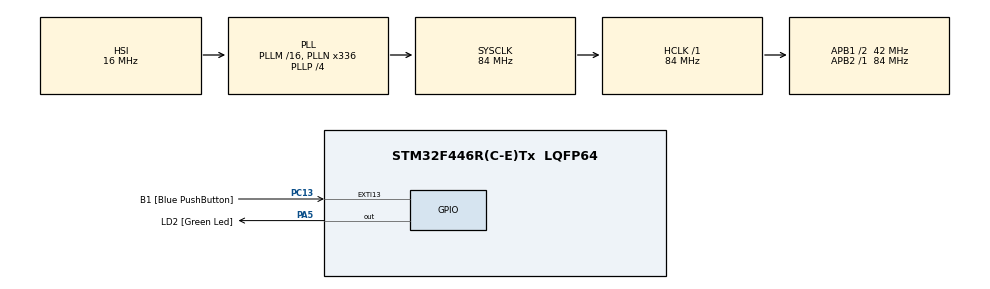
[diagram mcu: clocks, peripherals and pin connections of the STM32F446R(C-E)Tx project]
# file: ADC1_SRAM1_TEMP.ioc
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ADC1.Channel-0\#ChannelRegularConversion=ADC_CHANNEL_TEMPSENSOR
ADC1.Channel-1\#ChannelRegularConversion=ADC_CHANNEL_TEMPSENSOR
ADC1.Channel-10\#ChannelRegularConversion=ADC_CHANNEL_TEMPSENSOR
ADC1.Channel-11\#ChannelRegularConversion=ADC_CHANNEL_TEMPSENSOR
ADC1.Channel-12\#ChannelRegularConversion=ADC_CHANNEL_TEMPSENSOR
ADC1.Channel-13\#ChannelRegularConversion=ADC_CHANNEL_TEMPSENSOR
ADC1.Channel-14\#ChannelRegularConversion=ADC_CHANNEL_TEMPSENSOR
ADC1.Channel-15\#ChannelRegularConversion=ADC_CHANNEL_TEMPSENSOR
ADC1.Channel-2\#ChannelRegularConversion=ADC_CHANNEL_TEMPSENSOR
ADC1.Channel-3\#ChannelRegularConversion=ADC_CHANNEL_TEMPSENSOR
ADC1.Channel-4\#ChannelRegularConversion=ADC_CHANNEL_TEMPSENSOR
ADC1.Channel-5\#ChannelRegularConversion=ADC_CHANNEL_TEMPSENSOR
ADC1.Channel-6\#ChannelRegularConversion=ADC_CHANNEL_TEMPSENSOR
ADC1.Channel-7\#ChannelRegularConversion=ADC_CHANNEL_TEMPSENSOR
ADC1.Channel-8\#ChannelRegularConversion=ADC_CHANNEL_TEMPSENSOR
ADC1.Channel-9\#ChannelRegularConversion=ADC_CHANNEL_TEMPSENSOR
ADC1.ClockPrescaler=ADC_CLOCK_SYNC_PCLK_DIV4
ADC1.ContinuousConvMode=ENABLE
ADC1.DMAContinuousRequests=ENABLE
ADC1.DataAlign=ADC_DATAALIGN_RIGHT
ADC1.DiscontinuousConvMode=DISABLE
ADC1.EOCSelection=ADC_EOC_SINGLE_CONV
ADC1.EnableAnalogWatchDog=false
ADC1.ExternalTrigConv=ADC_SOFTWARE_START
ADC1.ExternalTrigConvEdge=ADC_EXTERNALTRIGCONVEDGE_NONE
ADC1.InjNumberOfConversion=0
ADC1.NbrOfConversion=16
ADC1.NbrOfConversionFlag=1
ADC1.Rank-0\#ChannelRegularConversion=1
ADC1.Rank-1\#ChannelRegularConversion=2
ADC1.Rank-10\#ChannelRegularConversion=11
ADC1.Rank-11\#ChannelRegularConversion=12
ADC1.Rank-12\#ChannelRegularConversion=13
ADC1.Rank-13\#ChannelRegularConversion=14
ADC1.Rank-14\#ChannelRegularConversion=15
ADC1.Rank-15\#ChannelRegularConversion=16
ADC1.Rank-2\#ChannelRegularConversion=3
ADC1.Rank-3\#ChannelRegularConversion=4
ADC1.Rank-4\#ChannelRegularConversion=5
ADC1.Rank-5\#ChannelRegularConversion=6
ADC1.Rank-6\#ChannelRegularConversion=7
ADC1.Rank-7\#ChannelRegularConversion=8
ADC1.Rank-8\#ChannelRegularConversion=9
ADC1.Rank-9\#ChannelRegularConversion=10
ADC1.Resolution=ADC_RESOLUTION_12B
ADC1.SamplingTime-0\#ChannelRegularConversion=ADC_SAMPLETIME_3CYCLES
ADC1.SamplingTime-1\#ChannelRegularConversion=ADC_SAMPLETIME_3CYCLES
ADC1.SamplingTime-10\#ChannelRegularConversion=ADC_SAMPLETIME_3CYCLES
ADC1.SamplingTime-11\#ChannelRegularConversion=ADC_SAMPLETIME_3CYCLES
ADC1.SamplingTime-12\#ChannelRegularConversion=ADC_SAMPLETIME_3CYCLES
ADC1.SamplingTime-13\#ChannelRegularConversion=ADC_SAMPLETIME_3CYCLES
ADC1.SamplingTime-14\#ChannelRegularConversion=ADC_SAMPLETIME_3CYCLES
ADC1.SamplingTime-15\#ChannelRegularConversion=ADC_SAMPLETIME_3CYCLES
ADC1.SamplingTime-2\#ChannelRegularConversion=ADC_SAMPLETIME_3CYCLES
ADC1.SamplingTime-3\#ChannelRegularConversion=ADC_SAMPLETIME_3CYCLES
ADC1.SamplingTime-4\#ChannelRegularConversion=ADC_SAMPLETIME_3CYCLES
ADC1.SamplingTime-5\#ChannelRegularConversion=ADC_SAMPLETIME_3CYCLES
ADC1.SamplingTime-6\#ChannelRegularConversion=ADC_SAMPLETIME_3CYCLES
ADC1.SamplingTime-7\#ChannelRegularConversion=ADC_SAMPLETIME_3CYCLES
ADC1.SamplingTime-8\#ChannelRegularConversion=ADC_SAMPLETIME_3CYCLES
ADC1.SamplingTime-9\#ChannelRegularConversion=ADC_SAMPLETIME_3CYCLES
ADC1.ScanConvMode=DISABLE
ADC1.master=1
Dma.ADC1.0.Direction=DMA_PERIPH_TO_MEMORY
Dma.ADC1.0.FIFOMode=DMA_FIFOMODE_ENABLE
Dma.ADC1.0.FIFOThreshold=DMA_FIFO_THRESHOLD_FULL
Dma.ADC1.0.Instance=DMA2_Stream4
Dma.ADC1.0.MemBurst=DMA_MBURST_SINGLE
Dma.ADC1.0.MemDataAlignment=DMA_MDATAALIGN_HALFWORD
Dma.ADC1.0.MemInc=DMA_MINC_ENABLE
Dma.ADC1.0.Mode=DMA_NORMAL
Dma.ADC1.0.PeriphBurst=DMA_PBURST_SINGLE
Dma.ADC1.0.PeriphDataAlignment=DMA_PDATAALIGN_HALFWORD
Dma.ADC1.0.PeriphInc=DMA_PINC_DISABLE
Dma.ADC1.0.Priority=DMA_PRIORITY_LOW
Dma.Request0=ADC1
Mcu.Family=STM32F4
Mcu.Name=STM32F446R(C-E)Tx
Mcu.Package=LQFP64
NVIC.DMA2_Stream4_IRQn=true\:0\:0\:false\:false\:true\:false
NVIC.EXTI15_10_IRQn=true\:0\:0\:false\:false\:true\:true
NVIC.PriorityGroup=NVIC_PRIORITYGROUP_0
PA13.GPIO_Label=TMS
PA13.Signal=SYS_JTMS-SWDIO
PA14.GPIO_Label=TCK
PA14.Signal=SYS_JTCK-SWCLK
PA2.GPIO_Label=USART_TX
PA2.Signal=USART2_TX
PA3.GPIO_Label=USART_RX
PA3.Signal=USART2_RX
PA5.GPIO_Label=LD2 [Green Led]
PA5.Signal=GPIO_Output
PB3.GPIO_Label=SWO
PB3.Signal=SYS_JTDO-SWO
PC13.GPIO_Label=B1 [Blue PushButton]
PC13.GPIO_ModeDefaultEXTI=GPIO_MODE_IT_FALLING
PC13.Signal=GPXTI13
PC14-OSC32_IN.Signal=RCC_OSC32_IN
PC15-OSC32_OUT.Signal=RCC_OSC32_OUT
PH0-OSC_IN.Signal=RCC_OSC_IN
PH1-OSC_OUT.Signal=RCC_OSC_OUT
ProjectManager.HeapSize=0x200
ProjectManager.StackSize=0x400
ProjectManager.TargetToolchain=MDK-ARM V5
RCC.AHBFreq_Value=84000000
RCC.APB1CLKDivider=RCC_HCLK_DIV2
RCC.APB1Freq_Value=42000000
RCC.APB1TimFreq_Value=84000000
RCC.APB2Freq_Value=84000000
RCC.APB2TimFreq_Value=84000000
RCC.CortexFreq_Value=84000000
RCC.FLatency-AdvancedSettings=FLASH_LATENCY_2
RCC.HCLKFreq_Value=84000000
RCC.HSE_VALUE=8000000
RCC.HSI_VALUE=16000000
RCC.LSE_VALUE=32768
RCC.PLLN=336
RCC.PLLP=RCC_PLLP_DIV4
RCC.SYSCLKFreq_VALUE=84000000
RCC.SYSCLKSource=RCC_SYSCLKSOURCE_PLLCLK
RCC.USBFreq_Value=168000000
RCC.VCOOutputFreq_Value=336000000
VP_ADC1_TempSens_Input.Mode=IN-TempSens
board=NUCLEO-F446RE

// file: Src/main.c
/**
  ******************************************************************************
  * File Name          : main.c
  * Description        : Main program body
  ******************************************************************************
  ** This notice applies to any and all portions of this file
  * that are not between comment pairs USER CODE BEGIN and
  * USER CODE END. Other portions of this file, whether
  * inserted by the user or by software development tools
  * are owned by their respective copyright owners.
  *
  * COPYRIGHT(c) 2018 STMicroelectronics
  *
  * Redistribution and use in source and binary forms, with or without modification,
  * are permitted provided that the following conditions are met:
  *   1. Redistributions of source code must retain the above copyright notice,
  *      this list of conditions and the following disclaimer.
  *   2. Redistributions in binary form must reproduce the above copyright notice,
  *      this list of conditions and the following disclaimer in the documentation
  *      and/or other materials provided with the distribution.
  *   3. Neither the name of STMicroelectronics nor the names of its contributors
  *      may be used to endorse or promote products derived from this software
  *      without specific prior written permission.
  *
  * THIS SOFTWARE IS PROVIDED BY THE COPYRIGHT HOLDERS AND CONTRIBUTORS "AS IS"
  * AND ANY EXPRESS OR IMPLIED WARRANTIES, INCLUDING, BUT NOT LIMITED TO, THE
  * IMPLIED WARRANTIES OF MERCHANTABILITY AND FITNESS FOR A PARTICULAR PURPOSE ARE
  * DISCLAIMED. IN NO EVENT SHALL THE COPYRIGHT HOLDER OR CONTRIBUTORS BE LIABLE
  * FOR ANY DIRECT, INDIRECT, INCIDENTAL, SPECIAL, EXEMPLARY, OR CONSEQUENTIAL
  * DAMAGES (INCLUDING, BUT NOT LIMITED TO, PROCUREMENT OF SUBSTITUTE GOODS OR
  * SERVICES; LOSS OF USE, DATA, OR PROFITS; OR BUSINESS INTERRUPTION) HOWEVER
  * CAUSED AND ON ANY THEORY OF LIABILITY, WHETHER IN CONTRACT, STRICT LIABILITY,
  * OR TORT (INCLUDING NEGLIGENCE OR OTHERWISE) ARISING IN ANY WAY OUT OF THE USE
  * OF THIS SOFTWARE, EVEN IF ADVISED OF THE POSSIBILITY OF SUCH DAMAGE.
  *
  ******************************************************************************
  */

#include "main.h"
#include "stm32f4xx_hal.h"

ADC_HandleTypeDef hadc1;
DMA_HandleTypeDef hdma_adc1;

/* USER CODE BEGIN PV */
/* Private variables ---------------------------------------------------------*/

/* USER CODE END PV */

void SystemClock_Config(void);
static void MX_GPIO_Init(void);
static void MX_DMA_Init(void);
static void MX_ADC1_Init(void);

/* USER CODE BEGIN PFP */
/* Private function prototypes -----------------------------------------------*/

/* USER CODE END PFP */

int main(void)
{

  /* MCU Configuration----------------------------------------------------------*/

  /* Reset of all peripherals, Initializes the Flash interface and the Systick. */
  HAL_Init();

  /* Configure the system clock */
  SystemClock_Config();

  /* Initialize all configured peripherals */
  MX_GPIO_Init();
  MX_DMA_Init();
  MX_ADC1_Init();

  /* Infinite loop */
  while (1)
  {

  }

}

/** System Clock Configuration
*/
void SystemClock_Config(void)
{

  RCC_OscInitTypeDef RCC_OscInitStruct;
  RCC_ClkInitTypeDef RCC_ClkInitStruct;

    /**Configure the main internal regulator output voltage
    */
  __HAL_RCC_PWR_CLK_ENABLE();

  __HAL_PWR_VOLTAGESCALING_CONFIG(PWR_REGULATOR_VOLTAGE_SCALE3);

    /**Initializes the CPU, AHB and APB busses clocks
    */
  RCC_OscInitStruct.OscillatorType = RCC_OSCILLATORTYPE_HSI;
  RCC_OscInitStruct.HSIState = RCC_HSI_ON;
  RCC_OscInitStruct.HSICalibrationValue = 16;
  RCC_OscInitStruct.PLL.PLLState = RCC_PLL_ON;
  RCC_OscInitStruct.PLL.PLLSource = RCC_PLLSOURCE_HSI;
  RCC_OscInitStruct.PLL.PLLM = 16;
  RCC_OscInitStruct.PLL.PLLN = 336;
  RCC_OscInitStruct.PLL.PLLP = RCC_PLLP_DIV4;
  RCC_OscInitStruct.PLL.PLLQ = 2;
  RCC_OscInitStruct.PLL.PLLR = 2;
  if (HAL_RCC_OscConfig(&RCC_OscInitStruct) != HAL_OK)
  {
    _Error_Handler(__FILE__, __LINE__);
  }

    /**Initializes the CPU, AHB and APB busses clocks
    */
  RCC_ClkInitStruct.ClockType = RCC_CLOCKTYPE_HCLK|RCC_CLOCKTYPE_SYSCLK
                              |RCC_CLOCKTYPE_PCLK1|RCC_CLOCKTYPE_PCLK2;
  RCC_ClkInitStruct.SYSCLKSource = RCC_SYSCLKSOURCE_PLLCLK;
  RCC_ClkInitStruct.AHBCLKDivider = RCC_SYSCLK_DIV1;
  RCC_ClkInitStruct.APB1CLKDivider = RCC_HCLK_DIV2;
  RCC_ClkInitStruct.APB2CLKDivider = RCC_HCLK_DIV1;

  if (HAL_RCC_ClockConfig(&RCC_ClkInitStruct, FLASH_LATENCY_2) != HAL_OK)
  {
    _Error_Handler(__FILE__, __LINE__);
  }

    /**Configure the Systick interrupt time
    */
  HAL_SYSTICK_Config(HAL_RCC_GetHCLKFreq()/1000);

    /**Configure the Systick
    */
  HAL_SYSTICK_CLKSourceConfig(SYSTICK_CLKSOURCE_HCLK);

  /* SysTick_IRQn interrupt configuration */
  HAL_NVIC_SetPriority(SysTick_IRQn, 0, 0);
}

/* ADC1 init function */
static void MX_ADC1_Init(void)
{

  ADC_ChannelConfTypeDef sConfig;

    /**Configure the global features of the ADC (Clock, Resolution, Data Alignment and number of conversion)
    */
  hadc1.Instance = ADC1;
  hadc1.Init.ClockPrescaler = ADC_CLOCK_SYNC_PCLK_DIV4;
  hadc1.Init.Resolution = ADC_RESOLUTION_12B;
  hadc1.Init.ScanConvMode = DISABLE;
  hadc1.Init.ContinuousConvMode = ENABLE;
  hadc1.Init.DiscontinuousConvMode = DISABLE;
  hadc1.Init.ExternalTrigConvEdge = ADC_EXTERNALTRIGCONVEDGE_NONE;
  hadc1.Init.ExternalTrigConv = ADC_SOFTWARE_START;
  hadc1.Init.DataAlign = ADC_DATAALIGN_RIGHT;
  hadc1.Init.NbrOfConversion = 16;
  hadc1.Init.DMAContinuousRequests = ENABLE;
  hadc1.Init.EOCSelection = ADC_EOC_SINGLE_CONV;
  if (HAL_ADC_Init(&hadc1) != HAL_OK)
  {
    _Error_Handler(__FILE__, __LINE__);
  }

    /**Configure for the selected ADC regular channel its corresponding rank in the sequencer and its sample time.
    */
  sConfig.Channel = ADC_CHANNEL_TEMPSENSOR;
  sConfig.Rank = 1;
  sConfig.SamplingTime = ADC_SAMPLETIME_3CYCLES;
  if (HAL_ADC_ConfigChannel(&hadc1, &sConfig) != HAL_OK)
  {
    _Error_Handler(__FILE__, __LINE__);
  }

    /**Configure for the selected ADC regular channel its corresponding rank in the sequencer and its sample time.
    */
  sConfig.Rank = 2;
  if (HAL_ADC_ConfigChannel(&hadc1, &sConfig) != HAL_OK)
  {
    _Error_Handler(__FILE__, __LINE__);
  }

    /**Configure for the selected ADC regular channel its corresponding rank in the sequencer and its sample time.
    */
  sConfig.Rank = 3;
  if (HAL_ADC_ConfigChannel(&hadc1, &sConfig) != HAL_OK)
  {
    _Error_Handler(__FILE__, __LINE__);
  }

    /**Configure for the selected ADC regular channel its corresponding rank in the sequencer and its sample time.
    */
  sConfig.Rank = 4;
  if (HAL_ADC_ConfigChannel(&hadc1, &sConfig) != HAL_OK)
  {
    _Error_Handler(__FILE__, __LINE__);
  }

    /**Configure for the selected ADC regular channel its corresponding rank in the sequencer and its sample time.
    */
  sConfig.Rank = 5;
  if (HAL_ADC_ConfigChannel(&hadc1, &sConfig) != HAL_OK)
  {
    _Error_Handler(__FILE__, __LINE__);
  }

    /**Configure for the selected ADC regular channel its corresponding rank in the sequencer and its sample time.
    */
  sConfig.Rank = 6;
  if (HAL_ADC_ConfigChannel(&hadc1, &sConfig) != HAL_OK)
  {
    _Error_Handler(__FILE__, __LINE__);
  }

    /**Configure for the selected ADC regular channel its corresponding rank in the sequencer and its sample time.
    */
  sConfig.Rank = 7;
  if (HAL_ADC_ConfigChannel(&hadc1, &sConfig) != HAL_OK)
  {
    _Error_Handler(__FILE__, __LINE__);
  }

    /**Configure for the selected ADC regular channel its corresponding rank in the sequencer and its sample time.
    */
  sConfig.Rank = 8;
  if (HAL_ADC_ConfigChannel(&hadc1, &sConfig) != HAL_OK)
  {
    _Error_Handler(__FILE__, __LINE__);
  }

    /**Configure for the selected ADC regular channel its corresponding rank in the sequencer and its sample time.
    */
  sConfig.Rank = 9;
  if (HAL_ADC_ConfigChannel(&hadc1, &sConfig) != HAL_OK)
  {
    _Error_Handler(__FILE__, __LINE__);
  }

    /**Configure for the selected ADC regular channel its corresponding rank in the sequencer and its sample time.
    */
  sConfig.Rank = 10;
  if (HAL_ADC_ConfigChannel(&hadc1, &sConfig) != HAL_OK)
  {
    _Error_Handler(__FILE__, __LINE__);
  }

    /**Configure for the selected ADC regular channel its corresponding rank in the sequencer and its sample time.
    */
  sConfig.Rank = 11;
  if (HAL_ADC_ConfigChannel(&hadc1, &sConfig) != HAL_OK)
  {
    _Error_Handler(__FILE__, __LINE__);
  }

    /**Configure for the selected ADC regular channel its corresponding rank in the sequencer and its sample time.
    */
  sConfig.Rank = 12;
  if (HAL_ADC_ConfigChannel(&hadc1, &sConfig) != HAL_OK)
  {
    _Error_Handler(__FILE__, __LINE__);
  }

    /**Configure for the selected ADC regular channel its corresponding rank in the sequencer and its sample time.
    */
  sConfig.Rank = 13;
  if (HAL_ADC_ConfigChannel(&hadc1, &sConfig) != HAL_OK)
  {
    _Error_Handler(__FILE__, __LINE__);
  }

    /**Configure for the selected ADC regular channel its corresponding rank in the sequencer and its sample time.
    */
  sConfig.Rank = 14;
  if (HAL_ADC_ConfigChannel(&hadc1, &sConfig) != HAL_OK)
  {
    _Error_Handler(__FILE__, __LINE__);
  }

    /**Configure for the selected ADC regular channel its corresponding rank in the sequencer and its sample time.
    */
  sConfig.Rank = 15;
  if (HAL_ADC_ConfigChannel(&hadc1, &sConfig) != HAL_OK)
  {
    _Error_Handler(__FILE__, __LINE__);
  }

    /**Configure for the selected ADC regular channel its corresponding rank in the sequencer and its sample time.
    */
  sConfig.Rank = 16;
  if (HAL_ADC_ConfigChannel(&hadc1, &sConfig) != HAL_OK)
  {
    _Error_Handler(__FILE__, __LINE__);
  }

}

static void MX_DMA_Init(void)
{
  /* DMA controller clock enable */
  __HAL_RCC_DMA2_CLK_ENABLE();

  /* DMA interrupt init */
  /* DMA2_Stream4_IRQn interrupt configuration */
  HAL_NVIC_SetPriority(DMA2_Stream4_IRQn, 0, 0);
  HAL_NVIC_EnableIRQ(DMA2_Stream4_IRQn);

}

/** Configure pins as
        * Analog
        * Input
        * Output
        * EVENT_OUT
        * EXTI
     PA2   ------> USART2_TX
     PA3   ------> USART2_RX
*/
static void MX_GPIO_Init(void)
{

  GPIO_InitTypeDef GPIO_InitStruct;

  /* GPIO Ports Clock Enable */
  __HAL_RCC_GPIOC_CLK_ENABLE();
  __HAL_RCC_GPIOH_CLK_ENABLE();
  __HAL_RCC_GPIOA_CLK_ENABLE();
  __HAL_RCC_GPIOB_CLK_ENABLE();

  /*Configure GPIO pin Output Level */
  HAL_GPIO_WritePin(LD2_GPIO_Port, LD2_Pin, GPIO_PIN_RESET);

  /*Configure GPIO pin : B1_Pin */
  GPIO_InitStruct.Pin = B1_Pin;
  GPIO_InitStruct.Mode = GPIO_MODE_IT_FALLING;
  GPIO_InitStruct.Pull = GPIO_NOPULL;
  HAL_GPIO_Init(B1_GPIO_Port, &GPIO_InitStruct);

  /*Configure GPIO pins : USART_TX_Pin USART_RX_Pin */
  GPIO_InitStruct.Pin = USART_TX_Pin|USART_RX_Pin;
  GPIO_InitStruct.Mode = GPIO_MODE_AF_PP;
  GPIO_InitStruct.Pull = GPIO_NOPULL;
  GPIO_InitStruct.Speed = GPIO_SPEED_FREQ_VERY_HIGH;
  GPIO_InitStruct.Alternate = GPIO_AF7_USART2;
  HAL_GPIO_Init(GPIOA, &GPIO_InitStruct);

  /*Configure GPIO pin : LD2_Pin */
  GPIO_InitStruct.Pin = LD2_Pin;
  GPIO_InitStruct.Mode = GPIO_MODE_OUTPUT_PP;
  GPIO_InitStruct.Pull = GPIO_NOPULL;
  GPIO_InitStruct.Speed = GPIO_SPEED_FREQ_LOW;
  HAL_GPIO_Init(LD2_GPIO_Port, &GPIO_InitStruct);

  /* EXTI interrupt init*/
  HAL_NVIC_SetPriority(EXTI15_10_IRQn, 0, 0);
  HAL_NVIC_EnableIRQ(EXTI15_10_IRQn);

}

/* USER CODE BEGIN 4 */

void HAL_ADC_ConvCpltCallback(ADC_HandleTypeDef* hadc)
{
  /* Prevent unused argument(s) compilation warning */
  UNUSED(hadc);
  /* NOTE : This function Should not be modified, when the callback is needed,
            the HAL_ADC_ConvCpltCallback could be implemented in the user file
   */
}

/* USER CODE END 4 */

void _Error_Handler(char * file, int line)
{
  while(1)
  {
  }
}

/************************ (C) COPYRIGHT STMicroelectronics *****END OF FILE****/
